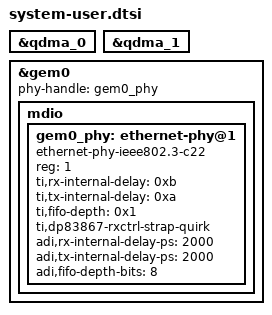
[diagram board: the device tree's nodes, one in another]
// SPDX-License-Identifier: MIT
// Copyright (C) 2025-2026, Opsero Electronic Design Inc.  All rights reserved.

/*
 * SoC-side / PL device-tree fixups for VEK280, layered on top of the
 * gen-machineconf / lopper-generated <...>-linux.dts (which already carries
 * the PS config and the PL xilinx_qdma PCIe Root Ports from the XSA via
 * pl.dtsi). Scoped to the Linux domain by device-tree.bbappend.
 *
 * PCIe outbound-window fix (qdma_0 / qdma_1 `ranges`):
 *   The SDT/lopper-generated `ranges` set the PCI base address to 0x0 (i.e.
 *   PCI 0x0 -> CPU 0xa8000000), but the Versal QDMA bridge forwards CPU
 *   addresses 1:1 to the PCIe bus. With the mismatched ranges the kernel
 *   assigns endpoint BARs near PCI 0x0 while CPU accesses through the window
 *   land at PCI 0xa8000000 -> nothing responds -> AXI decode error surfaces
 *   as an Asynchronous SError and the kernel panics in nvme_pci_enable.
 *   PetaLinux's HSI-generated DT uses 1:1 ranges (PCI addr == CPU addr); we
 *   override to match. VEK280 is a dual-QDMA design and uses the same ranges
 *   as VCK190 (HW-validated there).
 *
 *   Format: <pci_addr(3 cells) cpu_addr(2 cells) size(2 cells)>; first entry
 *   is the 32-bit MEM window, second is the 64-bit (prefetchable) window.
 *
 * NOTE: the PetaLinux VEK280 system-user.dtsi also adds a reserved-memory
 * block (pl_ddr / lpddr_memory) and the zocl PL node. Those are not required
 * for PCIe/NVMe boot and the parse-sdt SDT already describes the board memory,
 * so they are intentionally omitted here. Re-add only if a workload needs the
 * PL-DDR/LPDDR carveout.
 */

&qdma_0 {
	ranges = <0x02000000 0x0 0xa8000000  0x0 0xa8000000  0x0 0x04000000>,
		 <0x43000000 0x4 0x80000000  0x4 0x80000000  0x0 0x40000000>;
};

&qdma_1 {
	ranges = <0x02000000 0x0 0xac000000  0x0 0xac000000  0x0 0x04000000>,
		 <0x43000000 0x4 0xc0000000  0x4 0xc0000000  0x0 0x40000000>;
};

/* Board RJ45 (GEM0 = u198 PHY; GEM1 is not used on this board): the SDT
 * flow does not describe the board-level PHY, so Linux falls back to the
 * Generic PHY driver and the RGMII clock delays are never programmed -
 * the link negotiates 1G but passes no packets.
 * The PHY at MDIO addr 1 differs by board revision (official dts):
 *   versal-vek280-revA.dts: TI DP83867, RX 3.00 ns (0xb) / TX 2.75 ns (0xa)
 *   versal-vek280-revB.dts: ADI ADIN1300, RX/TX 2000 ps, FIFO 8 bits
 * so the node carries NO PHY-ID compatible: phylib reads the ID registers
 * and binds whichever driver matches (both are built in), and each driver
 * only reads its own ti,* / adi,* properties. reset-gpios omitted because
 * the SDT device tree does not define the gpio1 label - the PHY powers up
 * out of reset from straps. NOT yet verified on a VEK280.
 * No fixed MAC: the MAC stays random per boot (add a local-mac-address
 * property to pin one).
 */
&gem0 {
	phy-handle = <&gem0_phy>;
	mdio {
		#address-cells = <1>;
		#size-cells = <0>;
		gem0_phy: ethernet-phy@1 {
			compatible = "ethernet-phy-ieee802.3-c22";
			reg = <1>;
			ti,rx-internal-delay = <0xb>;
			ti,tx-internal-delay = <0xa>;
			ti,fifo-depth = <0x1>;
			ti,dp83867-rxctrl-strap-quirk;
			adi,rx-internal-delay-ps = <2000>;
			adi,tx-internal-delay-ps = <2000>;
			adi,fifo-depth-bits = <8>;
		};
	};
};
